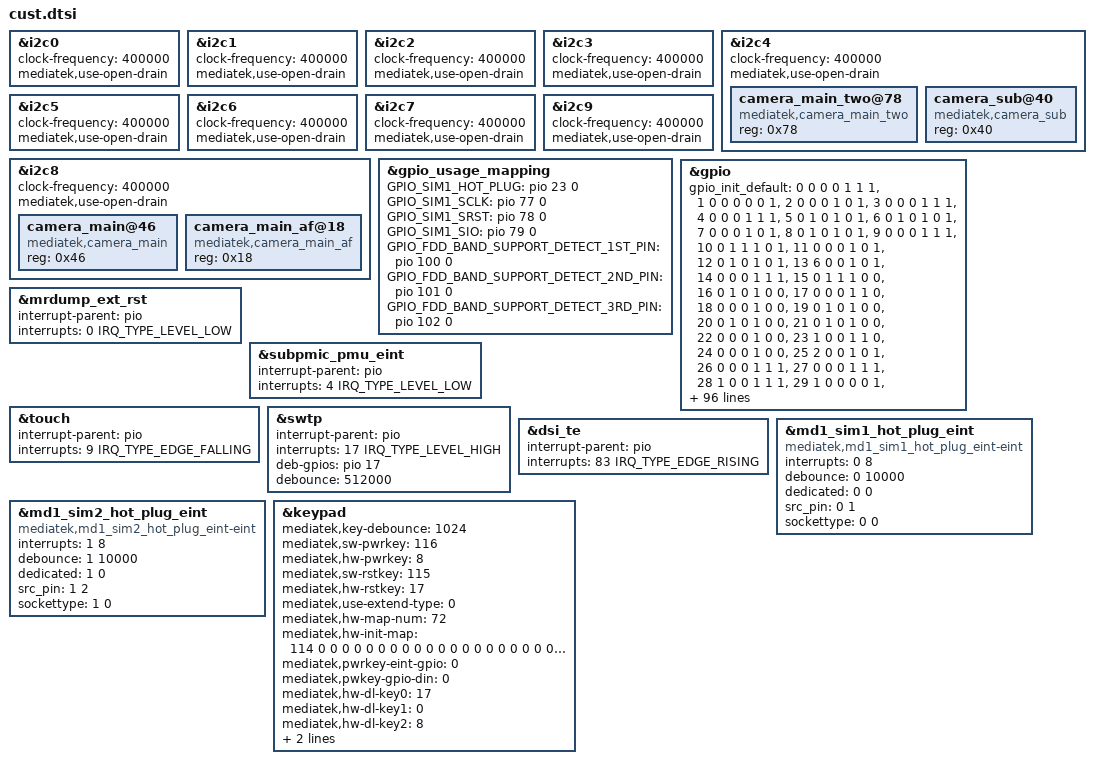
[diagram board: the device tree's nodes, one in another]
/*
 * Generated by MTK SP DrvGen Version: 3.5.160809 for MT6789.
 * 2023-07-21 19:20:00
 * Do Not Modify The File.
 * Copyright Mediatek Inc. (c) 2016.
*/

/*************************
 * ADC DTSI File
*************************/



/*************************
 * CLK_BUF DTSI File
*************************/



/*************************
 * I2C DTSI File
*************************/

&i2c0 {
	#address-cells = <1>;
	#size-cells = <0>;
	clock-frequency = <400000>;
	mediatek,use-open-drain;
};

&i2c1 {
	#address-cells = <1>;
	#size-cells = <0>;
	clock-frequency = <400000>;
	mediatek,use-open-drain;
};

&i2c2 {
	#address-cells = <1>;
	#size-cells = <0>;
	clock-frequency = <400000>;
	mediatek,use-open-drain;
};

&i2c3 {
	#address-cells = <1>;
	#size-cells = <0>;
	clock-frequency = <400000>;
	mediatek,use-open-drain;
};

&i2c4 {
	#address-cells = <1>;
	#size-cells = <0>;
	clock-frequency = <400000>;
	mediatek,use-open-drain;
	camera_main_two@78 {
		compatible = "mediatek,camera_main_two";
		reg = <0x78>;
		status = "okay";
	};

	camera_sub@40 {
		compatible = "mediatek,camera_sub";
		reg = <0x40>;
		status = "okay";
	};

};

&i2c5 {
	#address-cells = <1>;
	#size-cells = <0>;
	clock-frequency = <400000>;
	mediatek,use-open-drain;
};

&i2c6 {
	#address-cells = <1>;
	#size-cells = <0>;
	clock-frequency = <400000>;
	mediatek,use-open-drain;
};

&i2c7 {
	#address-cells = <1>;
	#size-cells = <0>;
	clock-frequency = <400000>;
	mediatek,use-open-drain;
};

&i2c8 {
	#address-cells = <1>;
	#size-cells = <0>;
	clock-frequency = <400000>;
	mediatek,use-open-drain;
	camera_main@46 {
		compatible = "mediatek,camera_main";
		reg = <0x46>;
		status = "okay";
	};

	camera_main_af@18 {
		compatible = "mediatek,camera_main_af";
		reg = <0x18>;
		status = "okay";
	};

};

&i2c9 {
	#address-cells = <1>;
	#size-cells = <0>;
	clock-frequency = <400000>;
	mediatek,use-open-drain;
};



/*************************
 * GPIO DTSI File
*************************/

&gpio_usage_mapping {
	GPIO_SIM1_HOT_PLUG = <&pio 23 0>;
	GPIO_SIM1_SCLK = <&pio 77 0>;
	GPIO_SIM1_SRST = <&pio 78 0>;
	GPIO_SIM1_SIO = <&pio 79 0>;
	GPIO_FDD_BAND_SUPPORT_DETECT_1ST_PIN = <&pio 100 0>;
	GPIO_FDD_BAND_SUPPORT_DETECT_2ND_PIN = <&pio 101 0>;
	GPIO_FDD_BAND_SUPPORT_DETECT_3RD_PIN = <&pio 102 0>;
};

&gpio{
	gpio_init_default = <0 0 0 0 1 1 1>,
		<1 0 0 0 0 0 1>,
		<2 0 0 0 1 0 1>,
		<3 0 0 0 1 1 1>,
		<4 0 0 0 1 1 1>,
		<5 0 1 0 1 0 1>,
		<6 0 1 0 1 0 1>,
		<7 0 0 0 1 0 1>,
		<8 0 1 0 1 0 1>,
		<9 0 0 0 1 1 1>,
		<10 0 1 1 1 0 1>,
		<11 0 0 0 1 0 1>,
		<12 0 1 0 1 0 1>,
		<13 6 0 0 1 0 1>,
		<14 0 0 0 1 1 1>,
		<15 0 1 1 1 0 0>,
		<16 0 1 0 1 0 0>,
		<17 0 0 0 1 1 0>,
		<18 0 0 0 1 0 0>,
		<19 0 1 0 1 0 0>,
		<20 0 1 0 1 0 0>,
		<21 0 1 0 1 0 0>,
		<22 0 0 0 1 0 0>,
		<23 1 0 0 1 1 0>,
		<24 0 0 0 1 0 0>,
		<25 2 0 0 1 0 1>,
		<26 0 0 0 1 1 1>,
		<27 0 0 0 1 1 1>,
		<28 1 0 0 1 1 1>,
		<29 1 0 0 0 0 1>,
		<30 1 0 0 0 0 1>,
		<31 1 0 0 0 0 1>,
		<32 1 0 0 0 0 1>,
		<33 1 0 0 1 0 1>,
		<34 0 0 0 1 1 0>,
		<35 0 0 0 1 0 0>,
		<36 0 0 0 1 1 1>,
		<37 0 0 0 1 1 1>,
		<38 2 0 0 0 0 1>,
		<39 2 0 0 0 0 1>,
		<40 2 0 0 0 0 1>,
		<41 2 0 0 1 0 1>,
		<42 0 0 0 1 0 1>,
		<43 0 0 0 1 0 1>,
		<44 4 0 0 0 0 1>,
		<45 4 0 0 1 0 1>,
		<46 6 0 0 0 0 0>,
		<47 6 0 0 1 0 0>,
		<48 6 0 0 0 0 0>,
		<49 6 0 0 1 0 0>,
		<50 0 1 0 1 0 1>,
		<51 0 0 0 1 0 1>,
		<52 0 1 0 1 0 1>,
		<53 0 0 0 1 0 1>,
		<54 0 0 0 1 0 1>,
		<55 0 0 0 1 0 1>,
		<56 0 0 0 1 0 1>,
		<57 0 0 0 1 0 1>,
		<58 0 0 0 1 0 1>,
		<59 0 0 0 1 0 1>,
		<60 0 0 0 1 0 1>,
		<61 0 0 0 1 0 1>,
		<62 0 0 0 1 0 1>,
		<63 0 0 0 1 0 1>,
		<64 0 0 0 1 0 1>,
		<65 0 0 0 1 0 1>,
		<66 1 0 0 1 1 1>,
		<67 0 0 0 1 1 1>,
		<68 0 0 0 1 0 1>,
		<69 0 0 0 1 1 1>,
		<71 1 0 0 1 0 1>,
		<72 1 0 0 1 0 1>,
		<73 1 0 0 1 0 1>,
		<74 1 0 0 1 0 1>,
		<75 1 0 0 1 0 1>,
		<76 1 0 0 1 0 1>,
		<77 1 0 0 0 0 1>,
		<78 1 0 0 0 0 1>,
		<79 1 0 0 1 1 1>,
		<80 0 1 1 1 0 1>,
		<81 0 0 0 1 0 1>,
		<82 0 0 0 1 0 1>,
		<83 1 0 0 1 0 1>,
		<84 1 0 0 1 0 1>,
		<85 0 1 0 1 0 0>,
		<86 1 0 0 1 0 0>,
		<87 1 0 0 1 0 0>,
		<88 1 0 0 1 0 0>,
		<89 1 0 0 1 0 0>,
		<90 1 0 0 1 0 0>,
		<91 1 0 0 1 0 0>,
		<92 1 0 0 1 0 0>,
		<93 1 0 0 1 0 0>,
		<94 1 0 0 1 0 0>,
		<95 1 0 0 1 0 0>,
		<96 1 0 0 1 0 0>,
		<97 0 0 0 1 0 0>,
		<98 0 0 0 1 0 0>,
		<99 0 0 0 1 0 0>,
		<100 0 0 0 1 0 0>,
		<101 0 0 0 1 0 0>,
		<102 0 0 0 1 0 0>,
		<103 2 0 0 1 1 0>,
		<104 2 0 0 1 1 0>,
		<105 0 0 0 0 0 1>,
		<106 0 0 0 1 1 0>,
		<107 0 0 0 1 0 0>,
		<108 0 1 0 1 0 0>,
		<109 0 0 0 0 0 0>,
		<110 0 1 1 1 0 0>,
		<111 1 0 0 1 0 0>,
		<112 1 0 0 0 0 0>,
		<113 1 0 0 1 0 0>,
		<114 0 0 0 1 0 0>,
		<115 0 0 0 1 0 0>,
		<116 0 0 0 1 0 0>,
		<117 0 0 0 1 0 0>,
		<118 0 0 0 1 0 0>,
		<119 0 0 0 1 0 0>,
		<120 0 0 0 1 0 0>,
		<121 0 0 0 1 0 0>,
		<122 1 0 0 0 0 0>,
		<123 1 0 0 0 0 0>,
		<124 1 0 0 1 0 0>,
		<125 1 0 0 1 0 0>,
		<126 1 0 0 1 0 0>,
		<127 0 0 0 1 0 0>,
		<128 1 0 0 1 0 0>,
		<129 0 0 0 1 0 0>,
		<130 0 0 0 1 0 1>,
		<131 0 0 0 1 0 1>,
		<132 2 0 0 1 1 0>,
		<133 2 0 0 1 1 0>,
		<134 1 0 0 1 1 1>,
		<135 1 0 0 1 1 1>,
		<136 1 0 0 1 1 1>,
		<137 1 0 0 1 1 1>,
		<138 1 0 0 1 1 0>,
		<139 1 0 0 1 1 0>,
		<140 1 0 0 1 1 1>,
		<141 1 0 0 1 1 1>,
		<142 1 0 0 1 1 1>,
		<143 1 0 0 1 1 1>,
		<144 1 0 0 1 1 1>,
		<145 1 0 0 1 1 1>,
		<146 1 0 0 1 1 1>,
		<147 1 0 0 1 1 1>,
		<148 2 0 0 1 1 1>,
		<149 2 0 0 1 1 1>,
		<150 0 1 0 1 0 1>,
		<151 0 1 0 1 0 1>,
		<152 0 1 1 1 0 1>,
		<153 0 1 0 1 0 1>,
		<154 0 1 0 1 0 1>,
		<155 0 1 0 1 0 1>,
		<156 0 1 0 1 0 1>,
		<157 0 1 0 1 0 1>,
		<158 0 1 0 1 0 1>,
		<159 0 1 0 1 0 0>,
		<160 1 0 0 0 0 1>,
		<161 1 0 0 0 0 1>,
		<162 1 0 0 0 0 1>,
		<163 1 0 0 1 0 1>,
		<164 1 0 0 0 0 1>,
		<165 1 0 0 0 0 1>,
		<166 1 0 0 0 0 1>,
		<167 1 0 0 1 0 1>,
		<168 1 0 0 0 0 0>,
		<169 1 0 0 0 0 1>,
		<170 1 0 0 0 0 1>,
		<171 1 0 0 0 0 1>,
		<172 1 0 0 0 0 1>,
		<173 1 0 0 1 0 1>,
		<174 1 0 0 1 0 1>,
		<175 1 0 0 1 0 1>,
		<176 1 0 0 1 0 1>,
		<177 0 0 0 1 0 0>,
		<178 0 0 0 1 0 0>,
		<179 0 0 0 1 0 0>,
		<180 0 0 0 1 0 0>,
		<181 0 0 0 1 0 0>,
		<182 0 0 0 1 0 0>,
		<183 0 0 0 1 0 0>,
		<184 0 0 0 1 0 0>,
		<185 0 0 0 1 0 0>,
		<186 0 0 0 1 0 1>,
		<187 0 0 0 1 0 1>,
		<188 0 0 0 1 0 0>,
		<189 0 0 0 1 0 0>,
		<190 0 0 0 1 0 0>,
		<191 0 0 0 1 0 0>,
		<192 0 0 0 1 0 0>,
		<193 0 0 0 1 0 0>,
		<194 0 0 0 1 0 0>,
		<195 0 0 0 1 0 0>,
		<196 0 0 0 1 0 0>,
		<197 0 0 0 1 0 0>,
		<198 0 0 0 1 0 0>,
		<199 0 0 0 1 0 0>,
		<200 0 0 0 1 0 0>,
		<201 0 0 0 1 0 0>,
		<202 0 0 0 1 0 0>,
		<203 0 0 0 1 0 0>,
		<204 0 0 0 1 0 0>,
		<205 0 0 0 1 0 0>,
		<206 0 0 0 1 0 0>,
		<207 0 0 0 1 0 0>,
		<208 0 0 0 1 0 0>,
		<209 0 0 0 1 0 0>,
		<210 0 0 0 1 0 0>,
		<211 0 0 0 1 0 0>,
		<212 0 0 0 1 0 0>,
		<213 0 0 0 1 0 0>,
		<214 0 0 0 1 0 0>,
		<215 0 0 0 1 0 0>,
		<216 0 0 0 1 0 0>,
		<217 0 0 0 1 0 0>,
		<218 0 0 0 1 0 0>,
		<219 0 0 0 1 0 0>,
		<220 0 0 0 1 0 0>,
		<221 0 0 0 1 0 0>;
};


/*************************
 * EINT DTSI File
*************************/

#include <dt-bindings/interrupt-controller/irq.h>
#include <dt-bindings/interrupt-controller/arm-gic.h>

&mrdump_ext_rst {
	interrupt-parent = <&pio>;
	interrupts = <0 IRQ_TYPE_LEVEL_LOW>;
	status = "okay";
};

&subpmic_pmu_eint {
	interrupt-parent = <&pio>;
	interrupts = <4 IRQ_TYPE_LEVEL_LOW>;
	status = "okay";
};

&touch {
	interrupt-parent = <&pio>;
	interrupts = <9 IRQ_TYPE_EDGE_FALLING>;
	status = "okay";
};

&swtp {
	interrupt-parent = <&pio>;
	interrupts = <17 IRQ_TYPE_LEVEL_HIGH>;
	deb-gpios = <&pio 17 0>;
	debounce = <512000>;
	status = "okay";
};

&dsi_te {
	interrupt-parent = <&pio>;
	interrupts = <83 IRQ_TYPE_EDGE_RISING>;
	status = "okay";
};



/*************************
 * MD1_EINT DTSI File
*************************/

&md1_sim1_hot_plug_eint {
	compatible = "mediatek,md1_sim1_hot_plug_eint-eint";
	interrupts = <0 8>;
	debounce = <0 10000>;
	dedicated = <0 0>;
	src_pin = <0 1>;
	sockettype = <0 0>;
	status = "okay";
};

&md1_sim2_hot_plug_eint {
	compatible = "mediatek,md1_sim2_hot_plug_eint-eint";
	interrupts = <1 8>;
	debounce = <1 10000>;
	dedicated = <1 0>;
	src_pin = <1 2>;
	sockettype = <1 0>;
	status = "okay";
};



/*************************
 * PMIC DTSI File
*************************/



/*************************
 * POWER DTSI File
*************************/



/*************************
 * KPD DTSI File
*************************/

&keypad {
	mediatek,key-debounce = <1024>;
	mediatek,sw-pwrkey = <116>;
	mediatek,hw-pwrkey = <8>;
	mediatek,sw-rstkey  = <115>;
	mediatek,hw-rstkey = <17>;
	mediatek,use-extend-type = <0>;
	/*HW Keycode [0~71] -> Linux Keycode*/
	mediatek,hw-map-num = <72>;
	mediatek,hw-init-map = <114 0 0 0 0 0 0 0 0 0 0 0 0 0 0 0 0 0 0 0 0 0 0 0 0 0 0 0 0 0 0 0 0 0 0 0 0 0 0 0 0 0 0 0 0 0 0 0 0 0 0 0 0 0 0 0 0 0 0 0 0 0 0 0 0 0 0 0 0 0 0 0 >;
	mediatek,pwrkey-eint-gpio = <0>;
	mediatek,pwkey-gpio-din  = <0>;
	mediatek,hw-dl-key0 = <17>;
	mediatek,hw-dl-key1 = <0>;
	mediatek,hw-dl-key2 = <8>;
	mediatek,hw-recovery-key = <17>;
	mediatek,hw-factory-key = <0>;
	status = "okay";
};


